# R7FA4L1BD register map
Vendor: Renesas Electronics Corporation; Series: RA4; File version: 0.90.02
CPU: CM33 r0p4, little endian, MPU, FPU, VTOR, 4 interrupt priority bits, 96 interrupts
Registers are 32-bit, read-write, reset 0x0 unless marked. A register's access mark holds for its fields unless they carry their own. Offsets are from the block's base; [hi:lo] are bit positions; {n}, {i} and the like mark numbered series; 'fields as' and 'values as' point back to an identical list.

## I3C
Base 0x4011F000
0x00 PRTS reset 0x1 — Protocol Selection Register
  [0] PRTMD — Protocol Mode
    0=I3C protocol mode; 1=I2C protocol mode
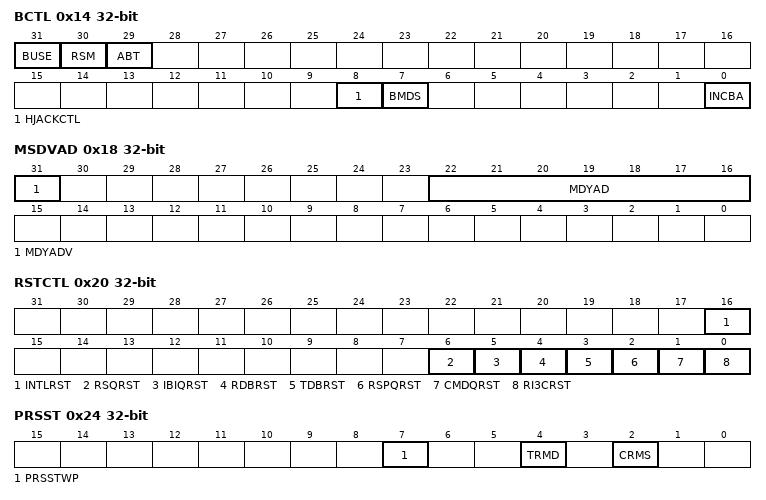
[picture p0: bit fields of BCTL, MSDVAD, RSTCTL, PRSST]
0x14 BCTL — Bus Control Register
  [31] BUSE — Bus Enable
    0=I3C bus operation is disabled; 1=I3C bus operation is enabled
  [30] RSM — Resume
    0=I3C is running; 1=I3C is suspended
  [29] ABT — Abort
    0=I3C is running; 1=I3C has aborted a transfer
  [8] HJACKCTL — Hot-Join Acknowledge Control
    0=ACK the Hot-Join request; 1=NACK and send broadcast CCC to disable Hot-Join
  [7] BMDS — Bus Mode Selection
    0=Legacy inclusive Bus mode disabled; 1=Legacy inclusive (mix) Bus mode enabled
  [0] INCBA — Include I3C Broadcast Address
    0=Do not include I3C broadcast address for private transfers; 1=Include I3C broadcast address for private transfers
0x18 MSDVAD — Master Device Address Register
  [31] MDYADV — Master Dynamic Address Valid
    0=The master dynamic address field is not valid; 1=The master dynamic address field is valid
  [22:16] MDYAD — Master Dynamic Address
0x20 RSTCTL — Reset Control Register
  [16] INTLRST — Internal Software Reset
    0=Releases of some registers and internal state; 1=Resets of some registers and internal state
  [6] RSQRST — Normal Receive Status Queue Software Reset
    0=The Normal Receive Status Queue in I3C is not flushed; 1=The Normal Receive Status Queue in I3C is flushed
  [5] IBIQRST — Normal IBI Queue Software Reset
    0=The Normal IBI Queues in I3C is not flushed; 1=The Normal IBI Queues in I3C is flushed
  [4] RDBRST — Normal Rx Data Buffer Software Reset
    0=The Normal Rx Data buffers in I3C is not flushed; 1=The Normal Rx Data buffers in I3C is flushed
  [3] TDBRST — Normal Tx Data Buffer Software Reset
    0=The Normal Tx Data buffers in I3C is not flushed; 1=The Normal Tx Data buffers in I3C is flushed
  [2] RSPQRST — Normal Response Queue Software Reset
    0=The Normal Response Queues in I3C is not flushed; 1=The Normal Response Queues in I3C is flushed
  [1] CMDQRST — Normal Command Queue Software Reset
    0=The Normal Command Queues in I3C is not flushed; 1=The Normal Command Queues in I3C is flushed
  [0] RI3CRST — I3C Software Reset
    0=Release I3C reset; 1=Initiate I3C reset
0x24 PRSST — Present State Register
  [7] PRSSTWP wo — Present State Write Protect
    0=CRMS bit is protected; 1=CRMS bit can be written when writing simultaneously with the value of the target bit
  [4] TRMD ro — Transmit/Receive Mode
    0=Receive mode; 1=Transmit mode
  [2] CRMS — Current Master
    0=The Master is not the Current Master, and must request and acquire bus ownership before initiating any transfer; 1=The Master is the Current Master, and as a result can initiate transfers
0x30 INST — Internal Status Register
  [10] INEF — Internal Error Flag
    0=I3C Internal Error has not detected; 1=I3C Internal Error has detected
0x34 INSTE — Internal Status Enable Register
  [10] INEE — Internal Error Enable
    0=Disable INST.INEF; 1=Enable INST.INEF
0x38 INIE — Internal Interrupt Enable Register
  [10] INEIE — Internal Error Interrupt Enable
    0=Disables Non-recoverable Internal Error Interrupt Signal; 1=Enables Non-recoverable Internal Error Interrupt Signal
0x3C INSTFC wo — Internal Status Force Register
  [10] INEFC — Internal Error Force
    0=Not force a specific interrupt; 1=Force a specific interrupt
0x44 DVCT ro — Device Characteristic Table Register
  [23:19] IDX — DCT Table Index
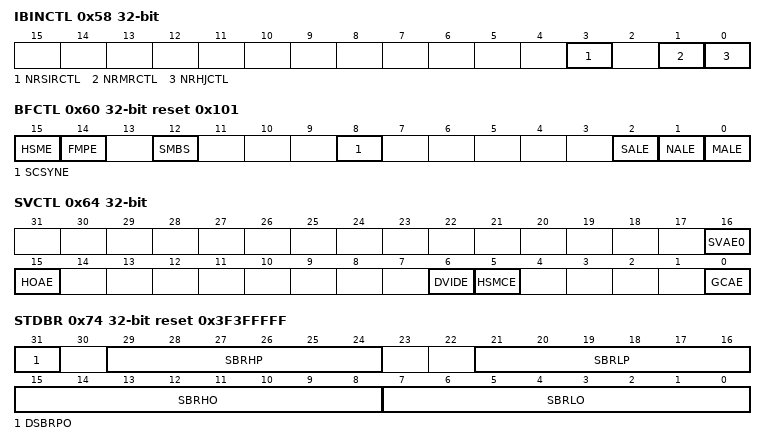
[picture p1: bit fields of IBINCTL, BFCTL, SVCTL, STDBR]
0x58 IBINCTL — IBI Notify Control Register
  [3] NRSIRCTL — Notify Rejected Slave Interrupt Request Control
    0=Do not pass rejected IBI Status to the Normal IBI Queue, if the incoming SIR is NACKed and is auto-disabled based on DVSIRRJ field in relevant DAT entry; 1=Pass rejected IBI Status to the Normal IBI Queue, if the incoming SIR is NACKed and is auto-disabled based on DVSIRRJ field in relevant DAT entry
  [1] NRMRCTL — Notify Rejected Master Request Control
    0=Do not pass rejected IBI Status to the Normal IBI Queue, if the incoming Master Request is NACKed and is auto-disabled based on DVMRRJ field in relevant DAT entry; 1=Pass rejected IBI Status to the Normal IBI Queue if the incoming Master Request is NACKed and is autodisabled based on DVMRRJ field in relevant DAT entry
  [0] NRHJCTL — Notify Rejected Hot-Join Control
    0=Do not pass rejected IBI Status to IBI Queue, if the incoming HotJoin request is NACKed and is autodisabled based on field HJACKCTL of BCTL; 1=Pass rejected IBI Status to the IBI Queue, if the incoming Hot Join request is NACKed and is autodisabled based on field HJACKCTL of BCTL
0x60 BFCTL reset 0x101 — Bus Function Control Register
  [15] HSME — High Speed Mode Enable
    0=Disable High Speed Mode; 1=Enable High Speed Mode
  [14] FMPE — Fast-mode Plus Enable
    0=No Fm+ slope control circuit uses for the I3C_SCL pin and I3C_SDA pin. (n = 0); 1=An Fm+ slope control circuit uses for the I3C_SCL pin and I3C_SDA pin. (n = 0)
  [12] SMBS — SMBus/I2C Bus Selection
    0=The I2C bus select; 1=The SMBus select
  [8] SCSYNE — SCL Synchronous Circuit Enable
    0=No SCL synchronous circuit uses; 1=An SCL synchronous circuit uses
  [2] SALE — Slave Arbitration-Lost Detection Enable
    0=Slave arbitration-lost detection disables; 1=Slave arbitration-lost detection enables
  [1] NALE — NACK Transmission Arbitration-Lost Detection Enable
    0=NACK transmission arbitration-lost detection disables; 1=NACK transmission arbitration-lost detection enables
  [0] MALE — Master Arbitration-Lost Detection Enable
    0=Master arbitration-lost detection disables. Disables the arbitration-lost detection function and does not clear the CRMS and TRMD bits in PRSST automatically when arbitration is lost.; 1=Master arbitration-lost detection enables. Enables the arbitration-lost detection function and clears the CRMS and TRMD bits in PRSST automatically when arbitration is lost.
0x64 SVCTL — Slave Control Register
  [16] SVAE0 — Slave Address Enable 0
    0=Slave n disables; 1=Slave n enables
  [15] HOAE — Host Address Enable
    0=Host address detection disables; 1=Host address detection enables
  [6] DVIDE — Device-ID Address Enable
    0=Device-ID address detection disables; 1=Device-ID address detection enables
  [5] HSMCE — Hs-mode Master Code Enable
    0=Hs-mode Master Code Detection disables; 1=Hs-mode Master Code Detection enables
  [0] GCAE — General Call Address Enable
    0=General call address detection disables; 1=General call address detection enables
0x70 REFCKCTL — Reference Clock Control Register
  [2:0] IREFCKS — Internal Reference Clock Selection
    0=TCLK/1 clock; 1=TCLK/2 clock; 2=TCLK/4 clock; 3=TCLK/8 clock; 4=TCLK/16 clock; 5=TCLK/32 clock; 6=TCLK/64 clock; 7=TCLK/128 clock
0x74 STDBR reset 0x3F3FFFFF — Standard Bit Rate Register
  [31] DSBRPO — Double the Standard Bit Rate Period for Open-Drain
    0=The time period set for SBRHO[7:0] and SBRLO[7:0] is not doubled; 1=The time period set for SBRHO[7:0] and SBRLO[7:0] is doubled
  [29:24] SBRHP — Standard Bit Rate High-Level Period Push-Pull
  [21:16] SBRLP — Standard Bit Rate Low-level Period Push-Pull
  [15:8] SBRHO — Standard Bit Rate High-Level Period Open-Drain
  [7:0] SBRLO — Standard Bit Rate Low-Level Period Open-Drain
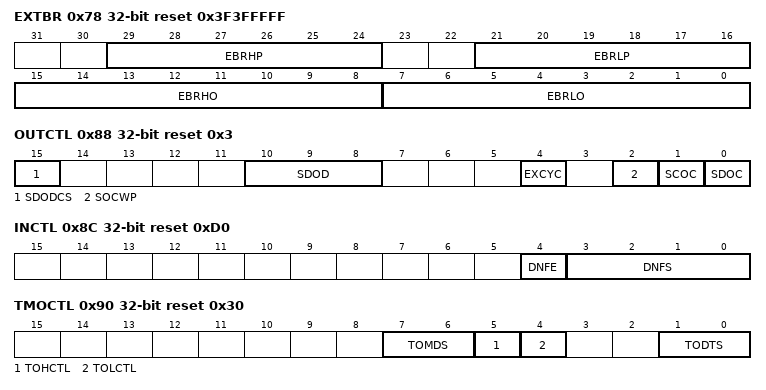
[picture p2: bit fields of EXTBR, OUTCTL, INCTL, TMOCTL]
0x78 EXTBR reset 0x3F3FFFFF — Extended Bit Rate Register
  [29:24] EBRHP — Extended Bit Rate High-Level Period Push-Pull
  [21:16] EBRLP — Extended Bit Rate Low-Level Period Push-Pull
  [15:8] EBRHO — Extended Bit Rate High-Level Period Open-Drain
  [7:0] EBRLO — Extended Bit Rate Low-Level Period Open-Drain
0x7C BFRECDT — Bus Free Condition Detection Time Register
  [8:0] FRECYC — Bus Free Condition Detection Cycle
0x80 BAVLCDT — Bus Available Condition Detection Time Register
  [8:0] AVLCYC — Bus Available Condition Detection Cycle
0x84 BIDLCDT — Bus Idle Condition Detection Time Register
  [17:0] IDLCYC — Bus Idle Condition Detection Cycle
0x88 OUTCTL reset 0x3 — Output Control Register
  [15] SDODCS — SDA Output Delay Clock Source Selection
    0=The internal reference clock (I3Cφ) is selected as the clock source of the SDA output delay counter; 1=The internal reference clock divided by 2 (I3Cφ/2) is selected as the clock source of the SDA output delay counter
  [10:8] SDOD — SDA Output Delay
    0=No output delay; 1=1 I3Cφ cycle (When OUTCTL.SDODCS = 0 (I3Cφ)) 1 or 2 I3Cφ cycles (When OUTCTL.SDODCS = 1 (I3Cφ/2)); 2=2 I3Cφ cycles (When OUTCTL.SDODCS = 0 (I3Cφ)) 3 or 4 I3Cφ cycles (When OUTCTL.SDODCS = 1 (I3Cφ/2)); 3=3 I3Cφ cycles (When OUTCTL.SDODCS = 0 (I3Cφ)) 5 or 6 I3Cφ cycles (When OUTCTL.SDODCS = 1 (I3Cφ/2)); 4=4 I3Cφ cycles (When OUTCTL.SDODCS = 0 (I3Cφ)) 7 or 8 I3Cφ cycles (When OUTCTL.SDODCS = 1 (I3Cφ/2)); 5=5 I3Cφ cycles (When OUTCTL.SDODCS = 0 (I3Cφ)) 9 or 10 I3Cφ cycles (When OUTCTL.SDODCS = 1 (I3Cφ/2)); 6=6 I3Cφ cycles (When OUTCTL.SDODCS = 0 (I3Cφ)) 11 or 12 I3Cφ cycles (When OUTCTL.SDODCS = 1 (I3Cφ/2)); 7=7 I3Cφ cycles (When OUTCTL.SDODCS = 0 (I3Cφ)) 13 or 14 I3Cφ cycles (When OUTCTL.SDODCS = 1 (I3Cφ/2))
  [4] EXCYC — Extra SCL Clock Cycle Output
    0=Does not output an extra SCL clock cycle (default); 1=Outputs an extra SCL clock cycle
  [2] SOCWP wo — SCL/SDA Output Control Write Protect
    0=Bits SCOC and SDOC are protected; 1=Bits SCOC and SDOC can be written (When writing simultaneously with the value of the target bit). This bit is read as 0.
  [1] SCOC — SCL Output Control
    0=I3C drives the I3C_SCL pin low; 1=I3C releases the I3C_SCL pin
  [0] SDOC — SDA Output Control
    0=I3C drives the I3C_SDA pin low; 1=I3C releases the I3C_SDA pin
0x8C INCTL reset 0xD0 — Input Control Register
  [4] DNFE — Digital Noise Filter Circuit Enable
    0=No digital noise filter circuit is used; 1=A digital noise filter circuit is used
  [3:0] DNFS — Digital Noise Filter Stage Selection
0x90 TMOCTL reset 0x30 — Timeout Control Register
  [7:6] TOMDS — Timeout Operation Mode Selection
    0=Timeout is detected during the following conditions: The bus is busy (BCST.BFREF = 0) in master mode.I3C’s own slave address is detected and the bus is busy in slave mode.The bus is free (BCST.BFREF = 1) while generation of a START condition is requested (CNDCTL.STCND = 1); 1=Timeout is detected while the bus is busy; 2=Timeout is detected while the bus is free; 3=Setting prohibited
  [5] TOHCTL — Timeout H Count Control
    0=Count is disabled while the I3C_SCL line is at a high level; 1=Count is enabled while the I3C_SCL line is at a high level
  [4] TOLCTL — Timeout L Count Control
    0=Count is disabled while the I3C_SCL line is at a low level; 1=Count is enabled while the I3C_SCL line is at a low level
  [1:0] TODTS — Timeout Detection Time Selection
    0=16bit-timeout; 1=14bit-timeout; 2=8bit-timeout; 3=6bit-timeout
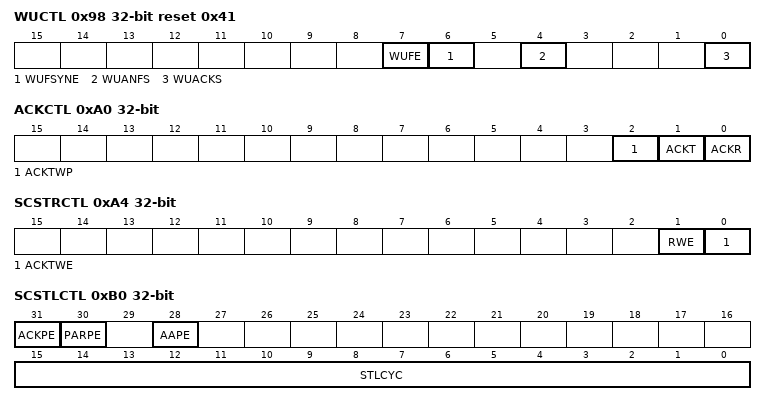
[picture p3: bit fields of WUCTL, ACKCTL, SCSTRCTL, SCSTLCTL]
0x98 WUCTL reset 0x41 — Wake-up Unit Control Register
  [7] WUFE — Wake-up function Enable
    0=Wake-up function disables; 1=Wake-up function enables
  [6] WUFSYNE — Wake-up function PCLK Synchronous Enable
    0=I3C asynchronous circuit enable; 1=I3C synchronous circuit enable
  [4] WUANFS — Wake-up Analog Noise Filter Selection
    0=Do not add the Wake-up analog filter; 1=Add the Wake-up analog filter
  [0] WUACKS — Wake-up Acknowledge Selection
0xA0 ACKCTL — Acknowledge Control Register
  [2] ACKTWP wo — ACKT Write Protect
    0=The ACKT bit are protected; 1=The ACKT bit can be written (when writing simultaneously with the value of the target bit). This bit is read as 0.
  [1] ACKT — Acknowledge Transmission
    0=A 0 is sent as the acknowledge bit (ACK transmission); 1=A 1 is sent as the acknowledge bit (NACK transmission)
  [0] ACKR ro — Acknowledge Reception
    0=A 0 is received as the acknowledge bit (ACK reception); 1=A 1 is received as the acknowledge bit (NACK reception)
0xA4 SCSTRCTL — SCL Stretch Control Register
  [1] RWE — Receive Wait Enable
    0=No WAIT (The period between ninth clock cycle and first clock cycle is not held low.); 1=WAIT (The period between ninth clock cycle and first clock cycle is held low.) Low-hold is released by reading NTDTBP0
  [0] ACKTWE — Acknowledge Transmission Wait Enable
    0=NTST.RDBFF0 is set at the rising edge of the ninth SCL clock cycle. (The I3C_SCL line is not held low at the falling edge of the eighth clock cycle.); 1=NTST.RDBFF0 is set at the rising edge of the eighth SCL clock cycle. (The I3C_SCL line is held low at the falling edge of the eighth clock cycle.) Low-hold is released by writing a value to the ACKCTL.ACKT bit.
0xB0 SCSTLCTL — SCL Stalling Control Register
  [31] ACKPE — ACK phase Enable
    0=Does not stall the SCL clock during the ACK/NACK phase; 1=Stall the SCL clock during the ACK/NACK phase
  [30] PARPE — Parity Phase Enable
    0=Does not stall the SCL clock during the parity bit period; 1=Stall the SCL clock during the parity bit period
  [28] AAPE — Assigned Address Phase Enable
    0=Does not stall the SCL clock during the address assignment phase; 1=Stall the SCL clock during address assignment phase
  [15:0] STLCYC — Stalling Cycle
0xC0 SVTDLG0 — Slave Transfer Data Length Register 0
  [31:16] STDLG — Slave Transfer Data Length
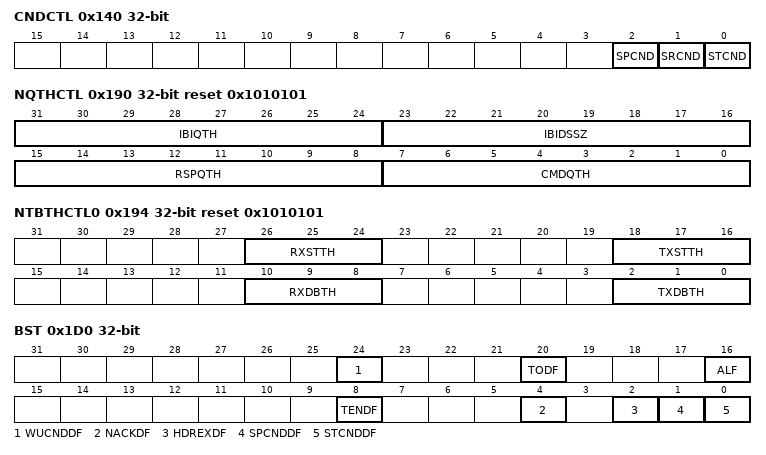
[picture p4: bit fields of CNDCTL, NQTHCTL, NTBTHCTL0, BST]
0x140 CNDCTL — Condition Control Register
  [2] SPCND — STOP (P) Condition Issuance
    0=Does not request to issue a STOP condition; 1=Requests to issue a STOP condition
  [1] SRCND — Repeated START (Sr) Condition Issuance
    0=Does not request to issue a Repeated START condition; 1=Requests to issue a Repeated START condition
  [0] STCND — START (S) Condition Issuance
    0=Does not request to issue a START condition; 1=Requests to issue a START condition
0x150 NCMDQP wo — Normal Command Queue Port Register
0x154 NRSPQP ro — Normal Response Queue Port Register
0x158 NTDTBP0 — Normal Transfer Data Buffer Port Register 0
0x158 NTDTBP0_BY 8-bit (alternate view of NTDTBP0) — Normal Transfer Data Buffer Port Register 0
0x17C NIBIQP — Normal IBI Queue Port Register
0x180 NRSQP ro — Normal Receive Status Queue Port Register
0x190 NQTHCTL reset 0x1010101 — Normal Queue Threshold Control Register
  [31:24] IBIQTH — Normal IBI Queue Threshold
    0=I3C Protocol mode (Master): Interrupt is generated when the Outstanding IBI Status count is 1 or more. I3C Protocol mode (Slave): Interrupt is issued when IBI Data Buffer is completely empty.; other=Others (I3C Protocol mode (Master): Interrupt is generated when the Outstanding IBI Status count is N + 1 or more. (N = CMDQTH[7:0]) I3C Protocol mode (Slave): Interrupt is issued when IBI Data Buffer contains N empties.)
  [23:16] IBIDSSZ — Normal IBI Data Segment Size
  [15:8] RSPQTH — Normal Response Queue Threshold
    0=Interrupt is issued when Normal Response Queue contains 1 entry (DWORD); other=Others (Interrupt is triggered when Normal Response Queue contains N+1 entries (DWORD). (N = CMDQTH[7:0]))
  [7:0] CMDQTH — Normal Command Queue Threshold
    0=Interrupt is issued when Normal Command Queue is completely empty; other=Others (Interrupt is issued when Normal Command Queue contains N empties. (N = CMDQTH[7:0]))
0x194 NTBTHCTL0 reset 0x1010101 — Normal Transfer Data Buffer Threshold Control Register 0
  [26:24] RXSTTH — Normal Rx Start Threshold
    0=Wait for 2 empty DWORDs; other=Others (Setting prohibited)
  [18:16] TXSTTH — Normal Tx Start Threshold
    0=Wait for 2 entry DWORDs; other=Others (Setting prohibited)
  [10:8] RXDBTH — Normal Rx Data Buffer Threshold
    0=Interrupt triggers at 2 Rx Buffer entries, DWORDs; other=Others (Setting prohibited)
  [2:0] TXDBTH — Normal Tx Data Buffer Threshold
    0=Interrupt triggers at 2 Tx Buffer empties, DWORDs; other=Others (Setting prohibited)
0x1C0 NRQTHCTL reset 0x1 — Normal Receive Status Queue Threshold Control Register
  [7:0] RSQTH — Normal Receive Status Queue Threshold
    0=Interrupt is issued when Normal Receive Status Queue contains 1 entry (DWORD); other=Others (Interrupt is triggered when Normal Receive Status Queue contains N+1 entries (DWORD). (N = RSQTH[7:0]))
0x1D0 BST — Bus Status Register
  [24] WUCNDDF — Wake-up Condition Detection Flag
    0=Wake-up is not detected; 1=Wake-up is detected
  [20] TODF — Timeout Detection Flag
    0=Timeout is not detected; 1=Timeout is detected
  [16] ALF — Arbitration Lost Flag
    0=Arbitration is not lost; 1=Arbitration is lost
  [8] TENDF — Transmit End Flag
    0=Data is being transmitted; 1=Data has been transmitted
  [4] NACKDF — NACK Detection Flag
    0=NACK is not detected; 1=NACK is detected
  [2] HDREXDF — HDR Exit Pattern Detection Flag
    0=HDR Exit Pattern is not detected; 1=HDR Exit Pattern is detected
  [1] SPCNDDF — STOP Condition Detection Flag
    0=STOP condition is not detected; 1=STOP condition is detected
  [0] STCNDDF — START Condition Detection Flag
    0=START condition is not detected; 1=START condition is detected
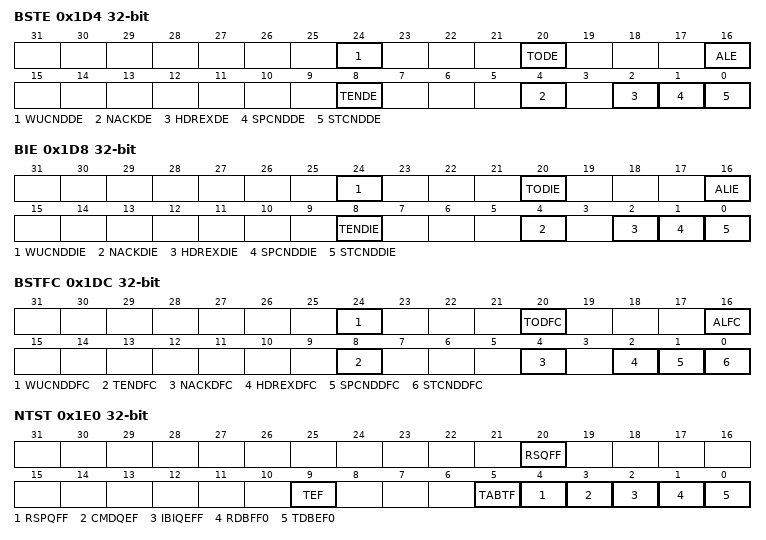
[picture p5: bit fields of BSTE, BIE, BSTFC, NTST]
0x1D4 BSTE — Bus Status Enable Register
  [24] WUCNDDE — Wake-up Condition Detection Enable
    0=Disables Wake-up Condition Detection Status logging; 1=Enables Wake-up Condition Detection Status logging
  [20] TODE — Timeout Detection Enable
    0=Disables Timeout Detection Interrupt Status logging; 1=Enables Timeout Detection Interrupt Status logging
  [16] ALE — Arbitration Lost Enable
    0=Disables Arbitration Lost Interrupt Status logging; 1=Enables Arbitration Lost Interrupt Status logging
  [8] TENDE — Transmit End Enable
    0=Disables Transmit End Interrupt Status logging; 1=Enables Transmit End Interrupt Status logging
  [4] NACKDE — NACK Detection Enable
    0=Disables NACK Detection Interrupt Status logging; 1=Enables NACK Detection Interrupt Status logging
  [2] HDREXDE — HDR Exit Pattern Detection Enable
    0=Disables HDR Exit Pattern Detection Interrupt Status logging; 1=Enables HDR Exit Pattern Detection Interrupt Status logging
  [1] SPCNDDE — STOP Condition Detection Enable
    0=Disables STOP condition Detection Interrupt Status logging; 1=Enables STOP condition Detection Interrupt Status logging
  [0] STCNDDE — START Condition Detection Enable
    0=Disables START condition Detection Interrupt Status logging; 1=Enables START condition Detection Interrupt Status logging
0x1D8 BIE — Bus Interrupt Enable Register
  [24] WUCNDDIE — Wake-up Condition Detection Interrupt Enable
    0=Disables Wake-up Condition Detection Interrupt Signal; 1=Enables Wake-up Condition Detection Interrupt Signal
  [20] TODIE — Timeout Detection Interrupt Enable
    0=Disables Timeout Detection Interrupt Signal; 1=Enables Timeout Detection Interrupt Signal
  [16] ALIE — Arbitration Lost Interrupt Enable
    0=Disables Arbitration Lost Interrupt Signal; 1=Enables Arbitration Lost Interrupt Signal
  [8] TENDIE — Transmit End Interrupt Enable
    0=Disables Transmit End Interrupt Signal; 1=Enables Transmit End Interrupt Signal
  [4] NACKDIE — NACK Detection Interrupt Enable
    0=Disables NACK Detection Interrupt Signal; 1=Enables NACK Detection Interrupt Signal
  [2] HDREXDIE — HDR Exit Pattern Detection Interrupt Enable
    0=Disables HDR Exit Pattern Detection Interrupt Signal; 1=Enables HDR Exit Pattern Detection Interrupt Signal
  [1] SPCNDDIE — STOP Condition Detection Interrupt Enable
    0=Disables STOP condition Detection Interrupt Signal; 1=Enables STOP condition Detection Interrupt Signal
  [0] STCNDDIE — START Condition Detection Interrupt Enable
    0=Disables START condition Detection Interrupt Signal; 1=Enables START condition Detection Interrupt Signal
0x1DC BSTFC — Bus Status Force Register
  [24] WUCNDDFC wo — Wake-up Condition Detection Force
    0=Not Force Wake-up Condition Detection Interrupt for software testing; 1=Force Wake-up Condition Detection Interrupt for software testing
  [20] TODFC wo — Timeout Detection Force
    0=Not Force Timeout Detection Interrupt for software testing; 1=Force Timeout Detection Interrupt for software testing
  [16] ALFC wo — Arbitration Lost Force
    0=Not Force Arbitration Lost Interrupt for software testing; 1=Force Arbitration Lost Interrupt for software testing
  [8] TENDFC wo — Transmit End Force
    0=Not Force Transmit End Interrupt for software testing; 1=Force Transmit End Interrupt for software testing
  [4] NACKDFC wo — NACK Detection Force
    0=Not Force NACK Detection Interrupt for software testing; 1=Force NACK Detection Interrupt for software testing
  [2] HDREXDFC wo — HDR Exit Pattern Detection Force
    0=Not Force HDR Exit Pattern Detection Interrupt for software testing; 1=Force HDR Exit Pattern Detection Interrupt for software testing
  [1] SPCNDDFC wo — STOP condition Detection Force
    0=Not Force STOP condition Detection Interrupt for software testing; 1=Force STOP condition Detection Interrupt for software testing
  [0] STCNDDFC wo — START condition Detection Force
    0=Not Force START condition Detection Interrupt for software testing; 1=Force START condition Detection Interrupt for software testing
0x1E0 NTST — Normal Transfer Status Register
  [20] RSQFF — Normal Receive Status Queue Full Flag
    0=The number of Normal Receive Status Queue entries is the NRQTHCTL.RSQTH threshold or less; 1=The number of Normal Receive Status Queue entries is more than the NRQTHCTL.RSQTH threshold
  [9] TEF — Normal Transfer Error Flag
    0=Normal Transfer Error does not occur; 1=Normal Transfer Error occurs. To clear, write 0 to this bit after 1 state is read.
  [5] TABTF — Normal Transfer Abort Flag
    0=Normal Transfer Abort does not occur; 1=Normal Transfer Abort occur. To clear, write 0 to this bit after 1 state is read.
  [4] RSPQFF — Normal Response Queue Full Flag
    0=The number of Normal Response Queue entries is the NQTHCTL.RSPQTH threshold or less; 1=The number of Normal Response Queue entries is more than the NQTHCTL.RSPQTH threshold
  [3] CMDQEF — Normal Command Queue Empty Flag
    0=If the NQTHCTL.CMDQTH = 0: The number of Normal Command Queue empties is less than the Normal Command Queue size. If the NQTHCTL.CMDQTH is other than 0: The number of Normal Command Queue empties is less than the NQTHCTL.CMDQTH threshold.; 1=If the NQTHCTL.CMDQTH = 0: The number of Normal Command Queue empties is the Normal Command Queue size. If the NQTHCTL.CMDQTH is other than 0: 1: The number of Normal Command Queue empties is the NQTHCTL.CMDQTH threshold or more.
  [2] IBIQEFF — Normal IBI Queue Empty/Full Flag
    0=For I3C protocol mode (Master): PRTS.PRTMD bit = 0, PRSST.CRMS bit = 1. The number of Normal IBI Queue entries is the NQTHCTL.IBIQTH threshold or less. For I3C protocol mode (Slave) : PRTS.PRTMD bit = 0, PRSST.CRMS bit = 0. If the NQTHCTL.IBIQTH = 0: The number of IBI Data Buffer empties is less than the IBI Data Buffer size. If the NQTHCTL.IBIQTH is other than 0: The number of IBI Data Buffer empties is less than the NQTHCTL.IBIQTH threshold.; 1=For I3C protocol mode (Master): PRTS.PRTMD bit = 0, PRSST.CRMS bit = 1. The number of Normal IBI Queue entries is more than the NQTHCTL.IBIQTH threshold. For I3C protocol mode (Slave) : PRTS.PRTMD bit = 0, PRSST.CRMS bit = 0. If the NQTHCTL.IBIQTH = 0: The number of IBI Data Buffer empties is the IBI Data Buffer size. If the NQTHCTL.IBIQTH is other than 0: The number of IBI Data Buffer empties is the NQTHCTL.IBIQTH threshold or more.
  [1] RDBFF0 — Normal Rx Data Buffer Full Flag 0
    0=For I2C protocol mode: PRTS.PRTMD bit = 1. Normal Rx Data Buffer contains no receive data. For I3C Protocol mode: PRTS.PRTMD bit = 0. The number of entries in the Normal Rx Data Buffer is less than the NTBTHCTL0.RXDBTH[2:0] threshold.; 1=For I2C protocol mode: PRTS.PRTMD bit = 1. Normal Rx Data Buffer contains receive data. For I3C Protocol mode: PRTS.PRTMD bit = 0. The number of entries in the Normal Rx Data Buffer is the NTBTHCTL0.RXDBTH[2:0] threshold or more.
  [0] TDBEF0 — Normal Tx Data Buffer Empty Flag 0
    0=For I2C protocol mode: PRTS.PRTMD bit = 1. Normal Tx Data Buffer contains transmit data. For I3C protocol mode: PRTS.PRTMD bit = 0. The number of empties in the Normal Tx Data Buffer is less than the NTBTHCTL0.TXDBTH[2:0] threshold.; 1=For I2C protocol mode: PRTS.PRTMD bit = 1. Normal Tx Data Buffer contains no transmit data. For I3C protocol mode: PRTS.PRTMD bit = 0. The number of empties in the Normal Tx Data Buffer is the NTBTHCTL0.TXDBTH[2:0] threshold or more.
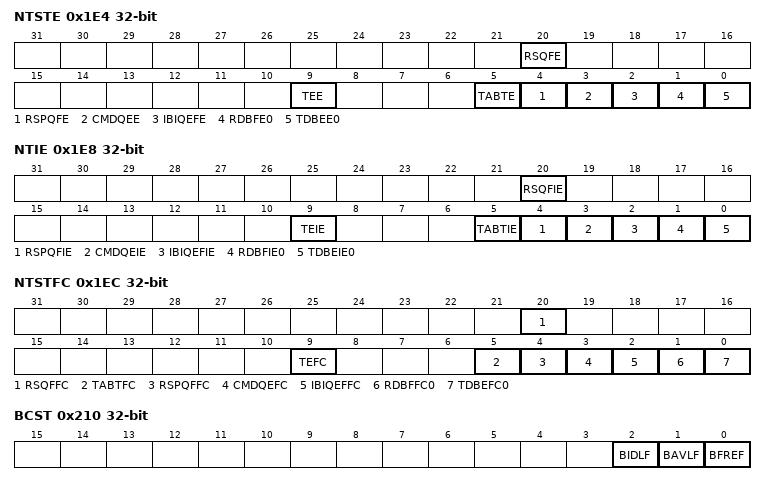
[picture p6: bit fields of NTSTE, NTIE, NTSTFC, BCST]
0x1E4 NTSTE — Normal Transfer Status Enable Register
  [20] RSQFE — Normal Receive Status Queue Full Enable
    0=Disables Normal Receive Status Queue Full Interrupt Status logging; 1=Enables Normal Receive Status Queue Full Interrupt Status logging
  [9] TEE — Normal Transfer Error Enable
    0=Disables Normal Transfer Error Interrupt Status logging; 1=Enables Normal Transfer Error Interrupt Status logging
  [5] TABTE — Normal Transfer Abort Enable
    0=Disables Normal Transfer Abort Interrupt Status logging; 1=Enables Normal Transfer Abort Interrupt Status logging
  [4] RSPQFE — Normal Response Queue Full Enable
    0=Disables Normal Response queue Full Interrupt Status logging; 1=Enables Normal Response queue Full Interrupt Status logging
  [3] CMDQEE — Normal Command Queue Empty Enable
    0=Disables Normal Command Queue Empty Interrupt Status logging; 1=Enables Normal Command Queue Empty Interrupt Status logging
  [2] IBIQEFE — Normal IBI Queue Empty/Full Enable
    0=Disables Normal IBI Queue Empty/Full Interrupt Status logging; 1=Enables Normal IBI Queue Empty/Full Interrupt Status logging
  [1] RDBFE0 — Normal Rx Data Buffer Full Enable 0
    0=Disables Normal Rx Data Buffer Full Interrupt Status logging; 1=Enables Normal Rx Data Buffer Full Interrupt Status logging
  [0] TDBEE0 — Normal Tx Data Buffer Empty Enable 0
    0=Disables Normal Tx Data Buffer Empty Interrupt Status logging; 1=Enables Normal Tx Data Buffer Empty Interrupt Status logging
0x1E8 NTIE — Normal Transfer Interrupt Enable Register
  [20] RSQFIE — Normal Receive Status Queue Full Interrupt Enable
    0=Disables Normal Receive Status Queue Full Interrupt Signal; 1=Enables Normal Receive Status Queue Full Interrupt Signal
  [9] TEIE — Normal Transfer Error Interrupt Enable
    0=Disables Normal Transfer Error Interrupt Signal; 1=Enables Normal Transfer Error Interrupt Signal
  [5] TABTIE — Normal Transfer Abort Interrupt Enable
    0=Disables Normal Transfer Abort Interrupt Signal; 1=Enables Normal Transfer Abort Interrupt Signal
  [4] RSPQFIE — Normal Response Queue Full Interrupt Enable
    0=Disables Normal Response Queue Full Interrupt Signal; 1=Enables Normal Response Queue Full Interrupt Signal
  [3] CMDQEIE — Normal Command Queue Empty Interrupt Enable
    0=Disables Normal Command Queue Empty Interrupt Signal; 1=Enables Normal Command Queue Empty Interrupt Signal
  [2] IBIQEFIE — Normal IBI Queue Empty/Full Interrupt Enable
    0=Disables Normal IBI Queue Empty/Full Interrupt Signal; 1=Enables Normal IBI Queue Empty/Full Interrupt Signal
  [1] RDBFIE0 — Normal Rx Data Buffer Full Interrupt Enable 0
    0=Disables Normal Rx Data Buffer Full Interrupt Signal; 1=Enables Normal Rx Data Buffer Full Interrupt Signal
  [0] TDBEIE0 — Normal Tx Data Buffer Empty Interrupt Enable 0
    0=Disables Normal Tx Data Buffer Empty Interrupt Signal; 1=Enables Normal Tx Data Buffer Empty Interrupt Signal
0x1EC NTSTFC — Normal Transfer Status Force Register
  [20] RSQFFC wo — Normal Receive Status Queue Full Force
    0=Not Force Normal Receive Status Queue Full Interrupt for software testing; 1=Force Normal Receive Status Queue Full Interrupt for software testing
  [9] TEFC wo — Normal Transfer Error Force
    0=Not Force Normal Transfer Error Interrupt for software testing; 1=Force Normal Transfer Error Interrupt for software testing
  [5] TABTFC wo — Normal Transfer Abort Force
    0=Not Force Normal Transfer Abort Interrupt for software testing; 1=Force Normal Transfer Abort Interrupt for software testing
  [4] RSPQFFC wo — Normal Response Queue Full Force
    0=Not Force Normal Response Queue Full Interrupt for software testing; 1=Force Normal Response Queue Full Interrupt for software testing
  [3] CMDQEFC wo — Normal Command Queue Empty Force
    0=Not Force Normal Command Queue Empty Interrupt for software testing; 1=Force Normal Command Queue Empty Interrupt for software testing
  [2] IBIQEFFC wo — Normal IBI Queue Empty/Full Force
    0=Not Force Normal IBI Queue Empty/Full Interrupt for software testing; 1=Force Normal IBI Queue Empty/Full Interrupt for software testing
  [1] RDBFFC0 wo — Normal Rx Data Buffer Full Force 0
    0=Not Force Normal Rx Data Buffer Full Interrupt for software testing; 1=Force Normal Rx Data Buffer Full Interrupt for software testing
  [0] TDBEFC0 wo — Normal Tx Data Buffer Empty Force 0
    0=Not Force Normal Tx Data Buffer Empty Interrupt for software testing; 1=Force Normal Tx Data Buffer Empty Interrupt for software testing
0x210 BCST ro — Bus Condition Status Register
  [2] BIDLF — Bus Idle Detection Flag
    0=Have not Detected Bus Idle; 1=Have Detected Bus Idle
  [1] BAVLF — Bus Available Detection Flag
    0=Have not Detected Bus Available; 1=Have Detected Bus Available
  [0] BFREF — Bus Free Detection Flag
    0=Have not Detected Bus Free; 1=Have Detected Bus Free
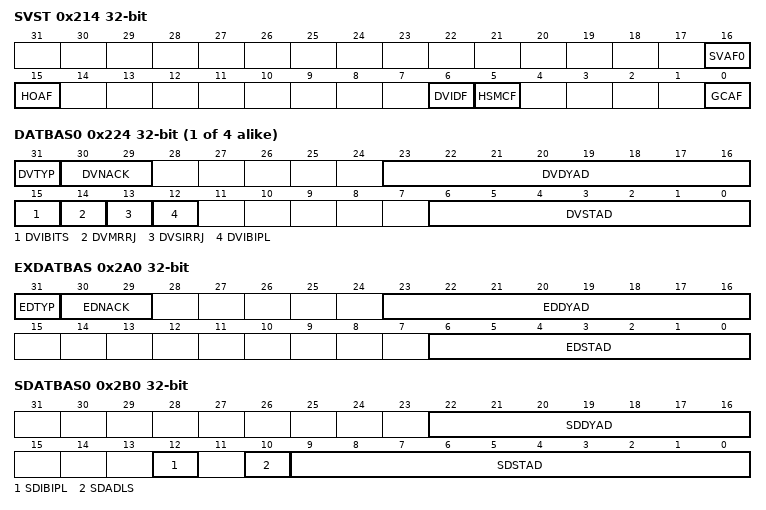
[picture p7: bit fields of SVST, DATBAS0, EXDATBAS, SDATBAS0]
0x214 SVST — Slave Status Register
  [16] SVAF0 — Slave Address Detection Flag 0
    0=Slave 0 does not detect; 1=Slave 0 detect
  [15] HOAF — Host Address Detection Flag
    0=Host address does not detect; 1=Host address detects. This bit set to 1 when the received slave address matches the host address (0001 000).
  [6] DVIDF — Device-ID Address Detection Flag
    0=Device-ID command does not detect; 1=Device-ID command detects. This bit set to 1 when the first frame received immediately after a START condition is detected matches a value of (device ID (1111 100) + 0[W]).
  [5] HSMCF — Hs-mode Master Code Detection Flag
    0=Hs-mode Master Code does not detect; 1=Hs-mode Master Code detects
  [0] GCAF — General Call Address Detection Flag
    0=General call address does not detect; 1=General call address detects
0x218 WUST ro — Wake-up Unit Operating Status Register
  [0] WUASYNF — Wake-up function asynchronous operation status flag
    0=I3C synchronous circuit enable condition; 1=I3C asynchronous circuit enable condition
{0x224+8i} DATBAS{i} (i=0..3) — Device Address Table Basic Register {i}
  [31] DVTYP — Device Type
    0=I3C Device; 1=I2C Device
  [30:29] DVNACK — Device NACK Retry Count
  [23:16] DVDYAD — Device I3C Dynamic Address
  [15] DVIBITS — Device IBI Time-stamp
    0=The Master shall not time-stamp IBIs from this Device with Master Time-stamps; 1=The Master shall time-stamp IBIs for this Device with Master Time-stamps
  [14] DVMRRJ — Device In-Band Master Request Reject
    0=This Device shall ACK Master Requests; 1=This Device shall NACK Master Requests and send the auto-disable command
  [13] DVSIRRJ — Device In-Band Slave Interrupt Request Reject
    0=This Device shall ACK the SIR; 1=This Device shall NACK the SIR and send the auto-disable CCC
  [12] DVIBIPL — Device IBI Payload
    0=IBIs from this Device do not carry a Data Payload; 1=IBIs from this Device do carry a Data Payload
  [6:0] DVSTAD — Device Static Address
0x2A0 EXDATBAS — Extended Device Address Table Basic Register
  [31] EDTYP — Extended Device Type
    0=I3C Device; 1=I2C Device
  [30:29] EDNACK — Extended Device NACK Retry Count
  [23:16] EDDYAD — Extended Device I3C Dynamic Address
  [6:0] EDSTAD — Extended Device Static Address
0x2B0 SDATBAS0 — Slave Device Address Table Basic Register 0
  [22:16] SDDYAD — Slave Device I3C Dynamic Address
  [12] SDIBIPL — Slave Device IBI Payload
    0=IBIs from this device do not carry a data payload; 1=IBIs from this device carry a data payload
  [10] SDADLS — Slave Device Address Length Selection
    0=Slave device address length 7 bits selected; 1=Slave device address length 10 bits selected. (I2C device only)
  [9:0] SDSTAD — Slave Device Static Address
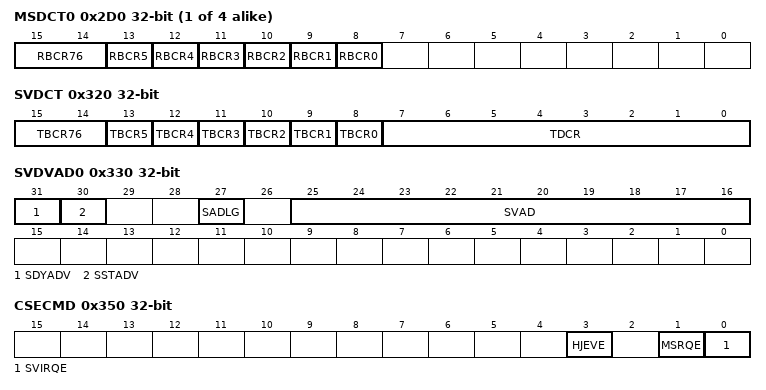
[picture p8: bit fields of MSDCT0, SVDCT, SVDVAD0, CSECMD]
{0x2D0+4i} MSDCT{i} (i=0..3) — Master Device Characteristic Table Register {i}
  [15:14] RBCR76 — Device Role
    0=I3C Slave; 1=I3C Master; other=Others (Setting prohibited)
  [13] RBCR5 — SDR Only / SDR and HDR Capable
    0=SDR only; 1=HDR Capable
  [12] RBCR4 — Bridge Identifier
    0=Not a Bridge Device; 1=A Bridge Device
  [11] RBCR3 — Offline Capable
    0=Device will always respond to I3C bus commands; 1=Device will not always respond to I3C bus commands
  [10] RBCR2 — IBI Payload
    0=No data byte follows the accepted IBI; 1=Mandatory one or more data bytes follow the accepted IBI. Data byte continuation is indicated by T-Bit.
  [9] RBCR1 — IBI Request Capable
    0=Not Capable; 1=Capable
  [8] RBCR0 — Max Data Speed Limitation
    0=No Limitation; 1=Limitation
0x320 SVDCT — Slave Device Characteristic Table Register
  [15:14] TBCR76 — Device Role
    0=I3C Slave; 1=I3C Master; other=Others (Setting prohibited)
  [13] TBCR5 — SDR Only / SDR and HDR Capable
    0=SDR only; 1=HDR Capable
  [12] TBCR4 — Bridge Identifier
    0=Not a Bridge Device; 1=A Bridge Device
  [11] TBCR3 — Offline Capable
    values as MSDCT0.RBCR3
  [10] TBCR2 — IBI Payload
    values as MSDCT0.RBCR2
  [9] TBCR1 — IBI Request Capable
    0=Not Capable; 1=Capable
  [8] TBCR0 — Max Data Speed Limitation
    0=No Limitation; 1=Limitation
  [7:0] TDCR — Transfer Device Characteristic Register
0x324 SDCTPIDL — Slave Device Characteristic Table Provisional ID Low Register
0x328 SDCTPIDH — Slave Device Characteristic Table Provisional ID High Register
0x330 SVDVAD0 ro — Slave Device Address Register 0
  [31] SDYADV — Slave Dynamic Address Valid
    0=Dynamic Address is disabled; 1=Dynamic Address is enabled
  [30] SSTADV — Slave Static Address Valid
    0=Slave address is disabled; 1=Slave address is enabled
  [27] SADLG — Slave Address Length
    0=The 7-bit address format is selected; 1=The 10-bit address format is selected
  [25:16] SVAD — Slave Address
0x350 CSECMD — CCC Slave Events Command Register
  [3] HJEVE — Hot-Join Event Enable
    0=DISABLED: Slave-initiated Hot-Join is Disabled by the Master to control; 1=ENABLED: Slave-initiated Hot-Join is Enabled by the Master to control
  [1] MSRQE — Mastership Requests Enable
    0=DISABLED: Mastership requests from Secondary Masters is Disabled by the Current Master to control; 1=ENABLED: Mastership requests from Secondary Masters is Enabled by the Current Master to control
  [0] SVIRQE — Slave Interrupt Requests Enable
    0=DISABLED: Slave-initiated Interrupts is Disabled by the Master to control; 1=ENABLED: Slave-initiated Interrupts is Enabled by the Master to control
0x354 CEACTST — CCC Enter Activity State Register
  [3:0] ACTST — Activity State
    1=ENTAS0 (1µs: Latency-free operation); 2=ENTAS1 (100 µs); 4=ENTAS2 (2 ms); 8=ENTAS3 (50 ms: Lowest-activity operation); other=Others (Setting prohibited)
0x358 CMWLG — CCC Max Write Length Register
  [15:0] MWLG — Max Write Length
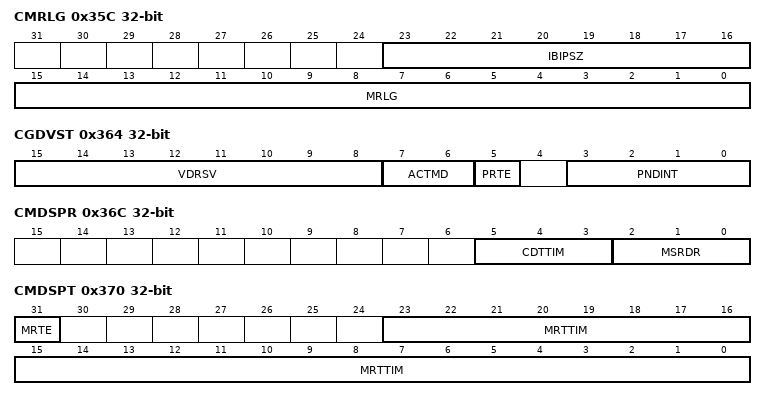
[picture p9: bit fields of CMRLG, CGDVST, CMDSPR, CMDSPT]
0x35C CMRLG — CCC Max Read Length Register
  [23:16] IBIPSZ — IBI Payload Size
  [15:0] MRLG — Max Read Length
0x360 CETSTMD ro — CCC Enter Test Mode Register
  [7:0] TSTMD — Test Mode
    0=Exit Test Mode This value removes all I3C devices from Test Mode; 1=Vendor Test Mode This value indicates that I3C devices shall return a random 32bit value in the provisional ID during the Dynamic Address Assignment procedure; other=Others (Setting prohibited)
0x364 CGDVST — CCC Get Device Status Register
  [15:8] VDRSV — Vendor Reserved
  [7:6] ACTMD — Slave Device’s current Activity Mode
    {v}=Activity Mode {v} (v=0..3)
  [5] PRTE — Protocol Error
    0=The Slave has not detected a protocol error since the last Status read; 1=The Slave has detected a protocol error since the last Status read
  [3:0] PNDINT — Pending Interrupt
0x368 CMDSPW — CCC Max Data Speed W (Write) Register
  [2:0] MSWDR — Maximum Sustained Write Data Rate
    0=fscl Max (default value); 1=8 MHz; 2=6 MHz; 3=4 MHz; 4=2 MHz; other=Others (Setting prohibited)
0x36C CMDSPR — CCC Max Data Speed R (Read) Register
  [5:3] CDTTIM — Clock to Data Turnaround Time (TSCO)
    0=8 ns or less (default value); {v}={v+8} ns or less (v=1..4); 7=TSCO is more than 12 ns, and is reported by private agreement; other=Others (Setting prohibited)
  [2:0] MSRDR — Maximum Sustained Read Data Rate
    values as CMDSPW.MSWDR
0x370 CMDSPT — CCC Max Data Speed T (Turnaround) Register
  [31] MRTE — Maximum Read Turnaround Time Enable
    0=Disables transmission of the Maximum Read Turnaround Time. (GETMXDS Format 1: Without Turnaround); 1=Enables transmission of the Maximum Read Turnaround Time. (GETMXDS Format 2: With Turnaround)
  [23:0] MRTTIM — Maximum Read Turnaround Time
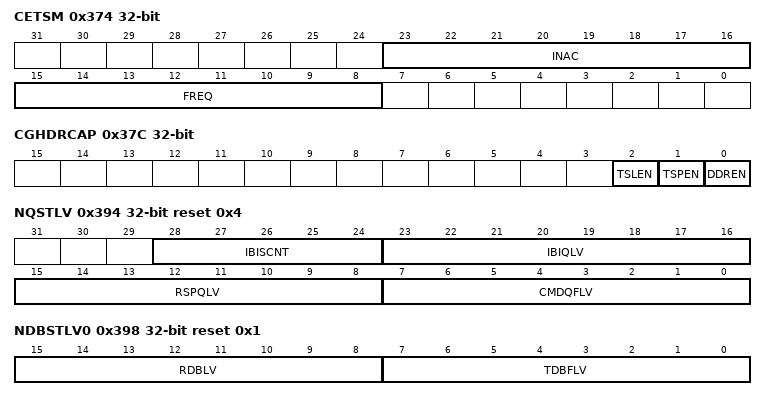
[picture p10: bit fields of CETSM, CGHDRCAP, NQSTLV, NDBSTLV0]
0x374 CETSM — CCC Exchange Timing Support Information M (Mode) Register
  [23:16] INAC — Inaccuracy Byte
  [15:8] FREQ — Frequency Byte
0x37C CGHDRCAP — CCC Get HDR Capability Register
  [2] TSLEN — HDR-TSL Operation Enable
    0=HDR-TSL Operation is Disabled; 1=HDR-TSL Operation is Enabled
  [1] TSPEN — HDR-TSP Operation Enable
    0=HDR-TSP Operation is Disabled; 1=HDR-TSP Operation is Enabled
  [0] DDREN — HDR-DDR Operation Enable
    0=HDR-DDR Operation is Disabled; 1=HDR-DDR Operation is Enabled
0x380 BITCNT ro — Bit Count Register
  [4:0] BCNT — Bit Counter
0x394 NQSTLV ro reset 0x4 — Normal Queue Status Level Register
  [28:24] IBISCNT — Normal IBI Status Count
  [23:16] IBIQLV — Normal IBI Queue Level
  [15:8] RSPQLV — Normal Response Queue Level
  [7:0] CMDQFLV — Normal Command Queue Free Level
0x398 NDBSTLV0 ro reset 0x1 — Normal Data Buffer Status Level Register 0
  [15:8] RDBLV — Normal Rx Data Buffer Level
  [7:0] TDBFLV — Normal Tx Data Buffer Free Level
0x3C0 NRSQSTLV ro — Normal Receive Status Queue Status Level Register
  [7:0] RSQLV — Normal Receive Status Queue Level
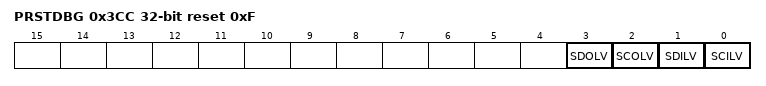
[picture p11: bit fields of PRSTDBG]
0x3CC PRSTDBG ro reset 0xF — Present State Debug Register
  [3] SDOLV — SDA Output Level
    0=I3C has driven the I3C_SDA pin low; 1=I3C has released the I3C_SDA pin
  [2] SCOLV — SCL Output Level
    0=I3C has driven the I3C_SCL pin low; 1=I3C has released the I3C_SCL pin
  [1] SDILV — I3C_SDA Line Signal Level
  [0] SCILV — I3C_SCL Line Signal Level
0x3D0 MSERRCNT ro — Master Error Counters Register
  [7:0] M2ECNT — M2 Error Counter
